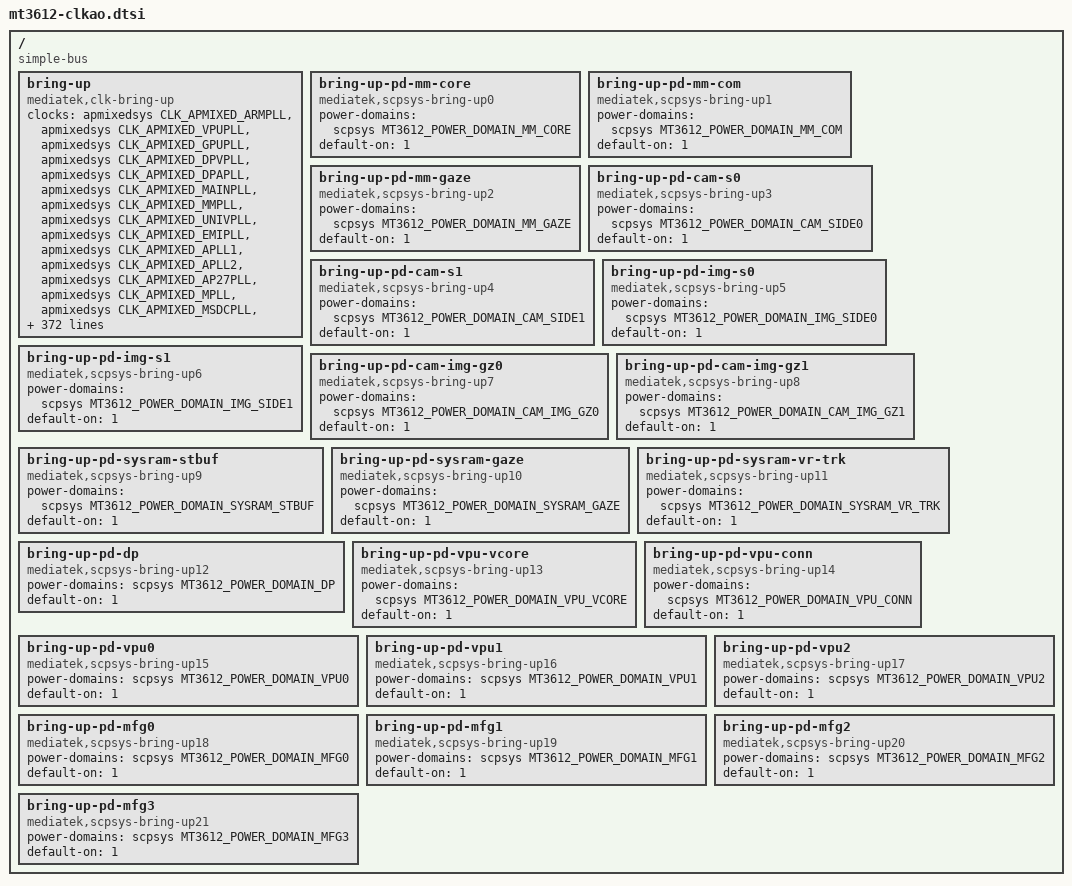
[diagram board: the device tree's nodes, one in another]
/ {
	compatible = "simple-bus";
	bring-up {
		compatible = "mediatek,clk-bring-up";
		clocks =
			<&apmixedsys CLK_APMIXED_ARMPLL>,
			<&apmixedsys CLK_APMIXED_VPUPLL>,
			<&apmixedsys CLK_APMIXED_GPUPLL>,
			<&apmixedsys CLK_APMIXED_DPVPLL>,
			<&apmixedsys CLK_APMIXED_DPAPLL>,
			<&apmixedsys CLK_APMIXED_MAINPLL>,
			<&apmixedsys CLK_APMIXED_MMPLL>,
			<&apmixedsys CLK_APMIXED_UNIVPLL>,
			<&apmixedsys CLK_APMIXED_EMIPLL>,
			<&apmixedsys CLK_APMIXED_APLL1>,
			<&apmixedsys CLK_APMIXED_APLL2>,
			<&apmixedsys CLK_APMIXED_AP27PLL>,
			<&apmixedsys CLK_APMIXED_MPLL>,
			<&apmixedsys CLK_APMIXED_MSDCPLL>,
			<&topckgen TOPCKGEN_SMI_CG>,
			<&topckgen TOPCKGEN_DSP_CG>,
			<&topckgen TOPCKGEN_IPU_IF_CG>,
			<&topckgen TOPCKGEN_SFLASH_CG>,
			<&topckgen TOPCKGEN_PWM_CG>,
			<&topckgen TOPCKGEN_CAMTG_CG>,
			<&topckgen TOPCKGEN_SENINF_CG>,
			<&topckgen TOPCKGEN_SENM0_CG>,
			<&topckgen TOPCKGEN_SENM1_CG>,
			<&topckgen TOPCKGEN_SENM2_CG>,
			<&topckgen TOPCKGEN_SENM3_CG>,
			<&topckgen TOPCKGEN_SENM4_CG>,
			<&topckgen TOPCKGEN_SENM5_CG>,
			<&topckgen TOPCKGEN_SENM6_CG>,
			<&topckgen TOPCKGEN_SENM7_CG>,
			<&topckgen TOPCKGEN_SENM8_CG>,
			<&topckgen TOPCKGEN_I2C_CG>,
			<&topckgen TOPCKGEN_UART_CG>,
			<&topckgen TOPCKGEN_SPI_CG>,
			<&topckgen TOPCKGEN_AXI_PERI_CG>,
			<&topckgen TOPCKGEN_USBH_SYS_CG>,
			<&topckgen TOPCKGEN_USBH_XCH_CG>,
			<&topckgen TOPCKGEN_USBD_SYS_CG>,
			<&topckgen TOPCKGEN_MSDC_CG>,
			<&topckgen TOPCKGEN_MSDC_HCLK_CG>,
			<&topckgen TOPCKGEN_AES_FDE_CG>,
			<&topckgen TOPCKGEN_AUD_INTBUS_CG>,
			<&topckgen TOPCKGEN_A1SYS_HP_CG>,
			<&topckgen TOPCKGEN_A2SYS_HP_CG>,
			<&topckgen TOPCKGEN_A3SYS_HP_CG>,
			<&topckgen TOPCKGEN_TDMIN_CG>,
			<&topckgen TOPCKGEN_TDMOUT_CG>,
			<&topckgen TOPCKGEN_PMICSPI_CG>,
			<&topckgen TOPCKGEN_MUTEXGEN_CG>,
			<&topckgen TOPCKGEN_STC_H27_CG>,
			<&topckgen TOPCKGEN_MFG_CG>,
			<&topckgen TOPCKGEN_CRYPTO_CG>,
			<&topckgen TOPCKGEN_IMG_S0_CG>,
			<&topckgen TOPCKGEN_IMG_S1_CG>,
			<&topckgen TOPCKGEN_MMSYS_COM_CG>,
			<&topckgen TOPCKGEN_FM_CG>,
			<&topckgen TOPCKGEN_MMSYS_CORE_CG>,
			<&topckgen TOPCKGEN_MM_SYSRAM0_CG>,
			<&topckgen TOPCKGEN_MM_SYSRAM1_CG>,
			<&topckgen TOPCKGEN_MM_SYSRAM2_CG>,
			<&topckgen TOPCKGEN_SENINF_GAZE_CG>,
			<&topckgen TOPCKGEN_CAM_S0_CG>,
			<&topckgen TOPCKGEN_CAM_S1_CG>,
			<&topckgen TOPCKGEN_CAM_GZ0_CG>,
			<&topckgen TOPCKGEN_CAM_GZ1_CG>,
			<&topckgen TOPCKGEN_MM_SYNCGEN_CG>,
			<&topckgen TOPCKGEN_ATB_CG>,
			<&topckgen TOPCKGEN_DISPPWM_CG>,
			<&topckgen TOPCKGEN_PMICGSPI_CG>,
			<&topckgen TOPCKGEN_DDDS_CG>,
			<&topckgen TOPCKGEN_DSP1_CG>,
			<&topckgen TOPCKGEN_DSP2_CG>,
			<&topckgen TOPCKGEN_DSP3_CG>,
			<&topckgen TOPCKGEN_HEADER_SYS_CG>,
			<&topckgen TOPCKGEN_DSI_REF_CG>,
			<&topckgen TOPCKGEN_SLICER_VID_CG>,
			<&topckgen TOPCKGEN_SLICER_DSC_CG>,
			<&topckgen TOPCKGEN_TPIU_CG>,
			<&topckgen TOPCKGEN_DDDS_VSP_CG>,
			<&topckgen TOPCKGEN_SCP_P_CK0_CG>,
			<&topckgen TOPCKGEN_SCP_P_CK1_CG>,
			<&topckgen TOPCKGEN_SCP_P_CK2_CG>,
			<&topckgen TOPCKGEN_SSUB_TOP_CK_EN>,
			<&topckgen TOPCKGEN_SSUB_PHY_CK_EN>,
			<&topckgen TOPCKGEN_SSUB_TOP_CK_EN_IP2>,
			<&topckgen TOPCKGEN_SSUB_PHY_CK_EN_IP2>,
			<&topckgen TOPCKGEN_F26M_DP_REF_CK_EN>,
			<&topckgen CLK_TOP_APLL12_DIV0>,
			<&topckgen CLK_TOP_APLL12_DIV1>,
			<&topckgen CLK_TOP_APLL12_DIV2>,
			<&topckgen CLK_TOP_APLL12_DIV3>,
			<&infracfg INFRACFG_AO_PMIC_CG_TMR>,
			<&infracfg INFRACFG_AO_PMIC_CG_AP>,
			<&infracfg INFRACFG_AO_PMIC_CG_MD>,
			<&infracfg INFRACFG_AO_PMIC_CG_CONN>,
			<&infracfg INFRACFG_AO_SCP_CG>,
			<&infracfg INFRACFG_AO_SEJ_CG>,
			<&infracfg INFRACFG_AO_APXGPT_CG>,
			<&infracfg INFRACFG_AO_DVFSRC_CG>,
			<&infracfg INFRACFG_AO_IO_TIMER_CG>,
			<&infracfg INFRACFG_AO_DEVAPC_MPU_CG>,
			<&infracfg INFRACFG_AO_FHCTL_CG>,
			<&infracfg INFRACFG_AO_PMIC_GSPI_CG>,
			<&infracfg INFRACFG_AO_AUXADC_CG>,
			<&infracfg INFRACFG_AO_DEVICE_APC_CG>,
			<&infracfg INFRACFG_AO_SMI_L2C_CG>,
			<&infracfg INFRACFG_AO_AUDIO_CG>,
			<&infracfg INFRACFG_AO_DRAMC_F26M_CG>,
			<&pericfg PERISYS_I2C9_CK_PDN>,
			<&pericfg PERISYS_I2C8_CK_PDN>,
			<&pericfg PERISYS_I2C7_CK_PDN>,
			<&pericfg PERISYS_I2C6_CK_PDN>,
			<&pericfg PERISYS_I2C5_CK_PDN>,
			<&pericfg PERISYS_I2C4_CK_PDN>,
			<&pericfg PERISYS_I2C3_CK_PDN>,
			<&pericfg PERISYS_I2C2_CK_PDN>,
			<&pericfg PERISYS_I2C1_CK_PDN>,
			<&pericfg PERISYS_I2C0_CK_PDN>,
			<&pericfg PERISYS_PWM15_CK_PDN>,
			<&pericfg PERISYS_PWM14_CK_PDN>,
			<&pericfg PERISYS_PWM13_CK_PDN>,
			<&pericfg PERISYS_PWM12_CK_PDN>,
			<&pericfg PERISYS_PWM11_CK_PDN>,
			<&pericfg PERISYS_PWM10_CK_PDN>,
			<&pericfg PERISYS_PWM9_CK_PDN>,
			<&pericfg PERISYS_PWM8_CK_PDN>,
			<&pericfg PERISYS_PWM7_CK_PDN>,
			<&pericfg PERISYS_PWM6_CK_PDN>,
			<&pericfg PERISYS_PWM5_CK_PDN>,
			<&pericfg PERISYS_PWM4_CK_PDN>,
			<&pericfg PERISYS_PWM3_CK_PDN>,
			<&pericfg PERISYS_PWM2_CK_PDN>,
			<&pericfg PERISYS_PWM1_CK_PDN>,
			<&pericfg PERISYS_PWM_CK_PDN>,
			<&pericfg PERISYS_SPI9_CK_PDN>,
			<&pericfg PERISYS_SPI8_CK_PDN>,
			<&pericfg PERISYS_SPI7_CK_PDN>,
			<&pericfg PERISYS_SPI6_CK_PDN>,
			<&pericfg PERISYS_SPI5_CK_PDN>,
			<&pericfg PERISYS_SPI4_CK_PDN>,
			<&pericfg PERISYS_SPI3_CK_PDN>,
			<&pericfg PERISYS_SPI2_CK_PDN>,
			<&pericfg PERISYS_SPI1_CK_PDN>,
			<&pericfg PERISYS_SPI0_CK_PDN>,
			<&pericfg PERISYS_UART9_CK_PDN>,
			<&pericfg PERISYS_UART8_CK_PDN>,
			<&pericfg PERISYS_UART7_CK_PDN>,
			<&pericfg PERISYS_UART6_CK_PDN>,
			<&pericfg PERISYS_UART5_CK_PDN>,
			<&pericfg PERISYS_UART4_CK_PDN>,
			<&pericfg PERISYS_UART3_CK_PDN>,
			<&pericfg PERISYS_UART2_CK_PDN>,
			<&pericfg PERISYS_UART1_CK_PDN>,
			<&pericfg PERISYS_UART0_CK_PDN>,
			<&pericfg PERISYS_MSDC0_AP_CK_PDN>,
			<&pericfg PERISYS_FLASH_CK_PDN>,
			<&pericfg PERISYS_USB_CK_PDN>,
			<&pericfg PERISYS_DISP_PWM1_CK_PDN>,
			<&pericfg PERISYS_DISP_PWM0_CK_PDN>,
			<&pericfg PERISYS_DEV_APC_CK_PDN>,
			<&pericfg PERISYS_DEBUGTOP_CK_PDN>,
			<&pericfg PERISYS_I2C19_CK_PDN>,
			<&pericfg PERISYS_I2C18_CK_PDN>,
			<&pericfg PERISYS_I2C17_CK_PDN>,
			<&pericfg PERISYS_I2C16_CK_PDN>,
			<&pericfg PERISYS_I2C15_CK_PDN>,
			<&pericfg PERISYS_I2C14_CK_PDN>,
			<&pericfg PERISYS_I2C13_CK_PDN>,
			<&pericfg PERISYS_I2C12_CK_PDN>,
			<&pericfg PERISYS_I2C11_CK_PDN>,
			<&pericfg PERISYS_I2C10_CK_PDN>,
			<&pericfg PERISYS_PWM32_CK_PDN>,
			<&pericfg PERISYS_PWM31_CK_PDN>,
			<&pericfg PERISYS_PWM30_CK_PDN>,
			<&pericfg PERISYS_PWM29_CK_PDN>,
			<&pericfg PERISYS_PWM28_CK_PDN>,
			<&pericfg PERISYS_PWM27_CK_PDN>,
			<&pericfg PERISYS_PWM26_CK_PDN>,
			<&pericfg PERISYS_PWM25_CK_PDN>,
			<&pericfg PERISYS_PWM24_CK_PDN>,
			<&pericfg PERISYS_PWM23_CK_PDN>,
			<&pericfg PERISYS_PWM22_CK_PDN>,
			<&pericfg PERISYS_PWM21_CK_PDN>,
			<&pericfg PERISYS_PWM20_CK_PDN>,
			<&pericfg PERISYS_PWM19_CK_PDN>,
			<&pericfg PERISYS_PWM18_CK_PDN>,
			<&pericfg PERISYS_PWM17_CK_PDN>,
			<&pericfg PERISYS_PWM16_CK_PDN>,
			<&mmsys_core MMSYS_CORE_SLCR0>,
			<&mmsys_core MMSYS_CORE_SLCR1>,
			<&mmsys_core MMSYS_CORE_SLCR2>,
			<&mmsys_core MMSYS_CORE_SLCR3>,
			<&mmsys_core MMSYS_CORE_MDP_RDMA0>,
			<&mmsys_core MMSYS_CORE_MDP_RDMA1>,
			<&mmsys_core MMSYS_CORE_MDP_RDMA2>,
			<&mmsys_core MMSYS_CORE_MDP_RDMA3>,
			<&mmsys_core MMSYS_CORE_MDP_PVRIC0>,
			<&mmsys_core MMSYS_CORE_MDP_PVRIC1>,
			<&mmsys_core MMSYS_CORE_MDP_PVRIC2>,
			<&mmsys_core MMSYS_CORE_MDP_PVRIC3>,
			<&mmsys_core MMSYS_CORE_DISP_RDMA0>,
			<&mmsys_core MMSYS_CORE_DISP_RDMA1>,
			<&mmsys_core MMSYS_CORE_DISP_RDMA2>,
			<&mmsys_core MMSYS_CORE_DISP_RDMA3>,
			<&mmsys_core MMSYS_CORE_DP_PAT_GEN0>,
			<&mmsys_core MMSYS_CORE_DP_PAT_GEN1>,
			<&mmsys_core MMSYS_CORE_DP_PAT_GEN2>,
			<&mmsys_core MMSYS_CORE_DP_PAT_GEN3>,
			<&mmsys_core MMSYS_CORE_LHC0>,
			<&mmsys_core MMSYS_CORE_LHC1>,
			<&mmsys_core MMSYS_CORE_LHC2>,
			<&mmsys_core MMSYS_CORE_LHC3>,
			<&mmsys_core MMSYS_CORE_DISP_WDMA0>,
			<&mmsys_core MMSYS_CORE_DISP_WDMA1>,
			<&mmsys_core MMSYS_CORE_DISP_WDMA2>,
			<&mmsys_core MMSYS_CORE_DISP_WDMA3>,
			<&mmsys_core MMSYS_CORE_DSC_MOUNT0>,
			<&mmsys_core MMSYS_CORE_DSC_MOUNT1>,
			<&mmsys_core MMSYS_CORE_DSC_MOUNT2>,
			<&mmsys_core MMSYS_CORE_DSC_MOUNT3>,
			<&mmsys_core MMSYS_CORE_DSI0_MM>,
			<&mmsys_core MMSYS_CORE_DSI1_MM>,
			<&mmsys_core MMSYS_CORE_DSI2_MM>,
			<&mmsys_core MMSYS_CORE_DSI3_MM>,
			<&mmsys_core MMSYS_CORE_DSI0_DIG>,
			<&mmsys_core MMSYS_CORE_DSI1_DIG>,
			<&mmsys_core MMSYS_CORE_DSI2_DIG>,
			<&mmsys_core MMSYS_CORE_DSI3_DIG>,
			<&mmsys_core MMSYS_CORE_CROP0>,
			<&mmsys_core MMSYS_CORE_CROP1>,
			<&mmsys_core MMSYS_CORE_CROP2>,
			<&mmsys_core MMSYS_CORE_CROP3>,
			<&mmsys_core MMSYS_CORE_RDMA_MOUT0>,
			<&mmsys_core MMSYS_CORE_RDMA_MOUT1>,
			<&mmsys_core MMSYS_CORE_RDMA_MOUT2>,
			<&mmsys_core MMSYS_CORE_RDMA_MOUT3>,
			<&mmsys_core MMSYS_CORE_RSZ0>,
			<&mmsys_core MMSYS_CORE_RSZ1>,
			<&mmsys_core MMSYS_CORE_RSZ_MOUT0>,
			<&mmsys_core MMSYS_CORE_P2S0>,
			<&mmsys_core MMSYS_CORE_DSC0>,
			<&mmsys_core MMSYS_CORE_DSC1>,
			<&mmsys_core MMSYS_CORE_DSI_LANE_SWAP>,
			<&mmsys_core MMSYS_CORE_SLICER_MM>,
			<&mmsys_core MMSYS_CORE_SLICER_VID>,
			<&mmsys_core MMSYS_CORE_SLICER_DSC>,
			<&mmsys_core MMSYS_CORE_LHC_SWAP>,
			<&mmsys_core MMSYS_CORE_SMI_LARB0>,
			<&mmsys_core MMSYS_CORE_SMI_LARB1>,
			<&mmsys_core MMSYS_CORE_SMI_LARB15>,
			<&mmsys_core MMSYS_CORE_SMI_LARB16>,
			<&mmsys_core MMSYS_CORE_LARB0_GALS>,
			<&mmsys_core MMSYS_CORE_LARB1_GALS>,
			<&mmsys_core MMSYS_CORE_LARB15_GALS>,
			<&mmsys_core MMSYS_CORE_LARB16_GALS>,
			<&mmsys_core MMSYS_CORE_RBFC0>,
			<&mmsys_core MMSYS_CORE_RBFC1>,
			<&mmsys_core MMSYS_CORE_RBFC2>,
			<&mmsys_core MMSYS_CORE_RBFC3>,
			<&mmsys_core MMSYS_CORE_SBRC>,
			<&mmsys_core MMSYS_CORE_MM_FAKE_ENG>,
			<&mmsys_core MMSYS_CORE_EVENT_TX>,
			<&mmsys_core MMSYS_CORE_CAMERA_SYNC>,
			<&mmsys_core MMSYS_CORE_MUTEX>,
			<&mmsys_core MMSYS_CORE_MUTEX_26M>,
			<&mmsys_core MMSYS_CORE_CRC>,
			<&mmsys_com MMSYS_CMM_PADDING0>,
			<&mmsys_com MMSYS_CMM_PADDING1>,
			<&mmsys_com MMSYS_CMM_PADDING2>,
			<&mmsys_com MMSYS_CMM_MDP_WPE_1_tx>,
			<&mmsys_com MMSYS_CMM_MDP_WPE_1_1_tx>,
			<&mmsys_com MMSYS_CMM_MDP_WPE_1_2_tx>,
			<&mmsys_com MMSYS_CMM_MDP_WPE_1>,
			<&mmsys_com MMSYS_CMM_MDP_FE>,
			<&mmsys_com MMSYS_CMM_WDMA_0>,
			<&mmsys_com MMSYS_CMM_WDMA_1>,
			<&mmsys_com MMSYS_CMM_WDMA_2>,
			<&mmsys_com MMSYS_CMM_MDP_FM>,
			<&mmsys_com MMSYS_CMM_RSZ_0>,
			<&mmsys_com MMSYS_CMM_RSZ_1>,
			<&mmsys_com MMSYS_CMM_MUTEX>,
			<&mmsys_com MMSYS_CMM_SMI_COMMON>,
			<&mmsys_com MMSYS_CMM_SMI_LARB3>,
			<&mmsys_com MMSYS_CMM_SMI_LARB21>,
			<&mmsys_com MMSYS_CMM_SMI_LARB2>,
			<&mmsys_com MMSYS_CMM_SMI_LARB20>,
			<&mmsys_com MMSYS_CMM_RBFC_REN_WPE1>,
			<&mmsys_com MMSYS_CMM_LARB2_FAKE_ENG>,
			<&mmsys_com MMSYS_CMM_SIDE_3_IN_CK_TX>,
			<&mmsys_com MMSYS_CMM_SIDE_2_IN_CK_TX>,
			<&mmsys_com MMSYS_CMM_SIDE_1_IN_CK_TX>,
			<&mmsys_com MMSYS_CMM_SIDE_0_IN_CK_TX>,
			<&mmsys_gaze MMSYS_GAZE_WPE_0_tx>,
			<&mmsys_gaze MMSYS_GAZE_WPE_0>,
			<&mmsys_gaze MMSYS_GAZE_WDMA_GAZE>,
			<&mmsys_gaze MMSYS_GAZE_MUTEX>,
			<&mmsys_gaze MMSYS_GAZE_SMI_LARB4>,
			<&mmsys_gaze MMSYS_GAZE_SMI_LARB22>,
			<&mmsys_gaze MMSYS_GAZE_RBFC_REN_WPE0>,
			<&mmsys_gaze MMSYS_GAZE_LARB4_FAKE_ENG>,
			<&mmsys_gaze MMSYS_GAZE_GAZE0_IN_CK_TX>,
			<&mmsys_gaze MMSYS_GAZE_GAZE1_IN_CK_TX>,
			<&vpusys_vcore VPUSYS_VCORE_AHB_CG>,
			<&vpusys_vcore VPUSYS_VCORE_AXI_CG>,
			<&vpusys_vconn VPUSYS_CONN_AHB_CG>,
			<&vpusys_vconn VPUSYS_CONN_AXI_CG>,
			<&vpusys_vconn VPUSYS_CONN_VPU_CG>,
			<&vpusys_core0 VPUSYS_CORE_0_VPU_CG>,
			<&vpusys_core0 VPUSYS_CORE_0_AXI_M_CG>,
			<&vpusys_core0 VPUSYS_CORE_0_JTAG>,
			<&vpusys_core1 VPUSYS_CORE_1_VPU_CG>,
			<&vpusys_core1 VPUSYS_CORE_1_AXI_M_CG>,
			<&vpusys_core1 VPUSYS_CORE_1_JTAG>,
			<&vpusys_core2 VPUSYS_CORE_2_VPU_CG>,
			<&vpusys_core2 VPUSYS_CORE_2_AXI_M_CG>,
			<&vpusys_core2 VPUSYS_CORE_2_JTAG>,
			<&audio_top AUDIO_TOP_PDN_TDMIN_BCK>,
			<&audio_top AUDIO_TOP_PDN_A3SYS>,
			<&audio_top AUDIO_TOP_PDN_A2SYS>,
			<&audio_top AUDIO_TOP_PDN_A1SYS>,
			<&audio_top AUDIO_TOP_PDN_DPRX_BCK>,
			<&audio_top AUDIO_TOP_PDN_TDMOUT_BCK>,
			<&audio_top AUDIO_TOP_PDN_AFE>,
			<&audio_top AUDIO_TOP_I2S_IN_CLK_CG>,
			<&audio_top AUDIO_TOP_I2S_OUT_CLK_CG>,
			<&camsys_gz0 CAMSYS_GZ0_RBFC_RRZO_0_CGPDN>,
			<&camsys_gz0 CAMSYS_GZ0_CAMSV_CGPDN>,
			<&camsys_gz0 CAMSYS_GZ0_SENINF_CGPDN>,
			<&camsys_gz0 CAMSYS_GZ0_CAMTG_CGPDN>,
			<&camsys_gz0 CAMSYS_GZ0_CAM_0_CGPDN>,
			<&camsys_gz0 CAMSYS_GZ0_SYSRAM_LARBX_CGPDN>,
			<&camsys_gz0 CAMSYS_GZ0_LARBX_CGPDN>,
			<&camsys_gz1 CAMSYS_GZ1_RBFC_RRZO_0_CGPDN>,
			<&camsys_gz1 CAMSYS_GZ1_CAMSV_CGPDN>,
			<&camsys_gz1 CAMSYS_GZ1_SENINF_CGPDN>,
			<&camsys_gz1 CAMSYS_GZ1_CAMTG_CGPDN>,
			<&camsys_gz1 CAMSYS_GZ1_CAM_0_CGPDN>,
			<&camsys_gz1 CAMSYS_GZ1_SYSRAM_LARBX_CGPDN>,
			<&camsys_gz1 CAMSYS_GZ1_LARBX_CGPDN>,
			<&imgsys_gz0 IMGSYS_GZ0_RBFC_IMG3O_A_CGPDN>,
			<&imgsys_gz0 IMGSYS_GZ0_RBFC_IMGI_A_CGPDN>,
			<&imgsys_gz0 IMGSYS_GZ0_DIP_A_CGPDN>,
			<&imgsys_gz1 IMGSYS_GZ1_RBFC_IMG3O_A_CGPDN>,
			<&imgsys_gz1 IMGSYS_GZ1_RBFC_IMGI_A_CGPDN>,
			<&imgsys_gz1 IMGSYS_GZ1_DIP_A_CGPDN>,
			<&camsys_side0 CAMSYS_SIDE0_BE1_CGPDN>,
			<&camsys_side0 CAMSYS_SIDE0_BE0_CGPDN>,
			<&camsys_side0 CAMSYS_SIDE0_RBFC_RRZO_1_CGPDN>,
			<&camsys_side0 CAMSYS_SIDE0_RBFC_RRZO_0_CGPDN>,
			<&camsys_side0 CAMSYS_SIDE0_CCU_CGPDN>,
			<&camsys_side0 CAMSYS_SIDE0_CAMSV_CGPDN>,
			<&camsys_side0 CAMSYS_SIDE0_SENINF_CGPDN>,
			<&camsys_side0 CAMSYS_SIDE0_CAMTG_CGPDN>,
			<&camsys_side0 CAMSYS_SIDE0_CAM_1_CGPDN>,
			<&camsys_side0 CAMSYS_SIDE0_CAM_0_CGPDN>,
			<&camsys_side0 CAMSYS_SIDE0_SYSRAM_LARBX_CGPDN>,
			<&camsys_side0 CAMSYS_SIDE0_LARBX_CGPDN>,
			<&camsys_side1 CAMSYS_SIDE1_BE1_CGPDN>,
			<&camsys_side1 CAMSYS_SIDE1_BE0_CGPDN>,
			<&camsys_side1 CAMSYS_SIDE1_RBFC_RRZO_1_CGPDN>,
			<&camsys_side1 CAMSYS_SIDE1_RBFC_RRZO_0_CGPDN>,
			<&camsys_side1 CAMSYS_SIDE1_CCU_CGPDN>,
			<&camsys_side1 CAMSYS_SIDE1_CAMSV_CGPDN>,
			<&camsys_side1 CAMSYS_SIDE1_SENINF_CGPDN>,
			<&camsys_side1 CAMSYS_SIDE1_CAMTG_CGPDN>,
			<&camsys_side1 CAMSYS_SIDE1_CAM_1_CGPDN>,
			<&camsys_side1 CAMSYS_SIDE1_CAM_0_CGPDN>,
			<&camsys_side1 CAMSYS_SIDE1_SYSRAM_LARBX_CGPDN>,
			<&camsys_side1 CAMSYS_SIDE1_LARBX_CGPDN>,
			<&imgsys_side0 IMGSYS_SIDE0_RBFC_IMG3O_B_CGPDN>,
			<&imgsys_side0 IMGSYS_SIDE0_RBFC_IMG3O_A_CGPDN>,
			<&imgsys_side0 IMGSYS_SIDE0_RBFC_IMGI_B_CGPDN>,
			<&imgsys_side0 IMGSYS_SIDE0_RBFC_IMGI_A_CGPDN>,
			<&imgsys_side0 IMGSYS_SIDE0_SYSRAM_LARBX_1_CGPDN>,
			<&imgsys_side0 IMGSYS_SIDE0_DIP_B_CGPDN>,
			<&imgsys_side0 IMGSYS_SIDE0_DIP_A_CGPDN>,
			<&imgsys_side0 IMGSYS_SIDE0_SYSRAM_LARBX_CGPDN>,
			<&imgsys_side0 IMGSYS_SIDE0_LARBX_CGPDN>,
			<&imgsys_side1 IMGSYS_SIDE1_RBFC_IMG3O_B_CGPDN>,
			<&imgsys_side1 IMGSYS_SIDE1_RBFC_IMG3O_A_CGPDN>,
			<&imgsys_side1 IMGSYS_SIDE1_RBFC_IMGI_B_CGPDN>,
			<&imgsys_side1 IMGSYS_SIDE1_RBFC_IMGI_A_CGPDN>,
			<&imgsys_side1 IMGSYS_SIDE1_SYSRAM_LARBX_1_CGPDN>,
			<&imgsys_side1 IMGSYS_SIDE1_DIP_B_CGPDN>,
			<&imgsys_side1 IMGSYS_SIDE1_DIP_A_CGPDN>,
			<&imgsys_side1 IMGSYS_SIDE1_SYSRAM_LARBX_CGPDN>,
			<&imgsys_side1 IMGSYS_SIDE1_LARBX_CGPDN>;
		clock-names =
			"0", "1", "2", "3", "4", "5", "6", "7", "8", "9",
			"10", "11", "12", "13", "14", "15", "16", "17", "18",
			"19", "20", "21", "22", "23", "24", "25", "26", "27",
			"28", "29", "30", "31", "32", "33", "34", "35", "36",
			"37", "38", "39", "40", "41", "42", "43", "44", "45",
			"46", "47", "48", "49", "50", "51", "52", "53", "54",
			"55", "56", "57", "58", "59", "60", "61", "62", "63",
			"64", "65", "66", "67", "68", "69", "70", "71", "72",
			"73", "74", "75", "76", "77", "78", "79", "80", "81",
			"82", "83", "84", "85", "86", "87", "88", "89", "90",
			"91", "92", "93", "94", "95", "96", "97", "98", "99",
			"100", "101", "102", "103", "104", "105", "106", "107",
			"108", "109", "110", "111", "112", "113", "114", "115",
			"116", "117", "118", "119", "120", "121", "122", "123",
			"124", "125", "126", "127", "128", "129", "130", "131",
			"132", "133", "134", "135", "136", "137", "138", "139",
			"140", "141", "142", "143", "144", "145", "146", "147",
			"148", "149", "150", "151", "152", "153", "154", "155",
			"156", "157", "158", "159", "160", "161", "162", "163",
			"164", "165", "166", "167", "168", "169", "170", "171",
			"172", "173", "174", "175", "176", "177", "178", "179",
			"180", "181", "182", "183", "184", "185", "186", "187",
			"188", "189", "190", "191", "192", "193", "194", "195",
			"196", "197", "198", "199", "200", "201", "202", "203",
			"204", "205", "206", "207", "208", "209", "210", "211",
			"212", "213", "214", "215", "216", "217", "218", "219",
			"220", "221", "222", "223", "224", "225", "226", "227",
			"228", "229", "230", "231", "232", "233", "234", "235",
			"236", "237", "238", "239", "240", "241", "242", "243",
			"244", "245", "246", "247", "248", "249", "250", "251",
			"252", "253", "254", "255", "256", "257", "258", "259",
			"260", "261", "262", "263", "264", "265", "266", "267",
			"268", "269", "270", "271", "272", "273", "274", "275",
			"276", "277", "278", "279", "280", "281", "282", "283",
			"284", "285", "286", "287", "288", "289", "290", "291",
			"292", "293", "294", "295", "296", "297", "298", "299",
			"300", "301", "302", "303", "304", "305", "306", "307",
			"308", "309", "310", "311", "312", "313", "314", "315",
			"316", "317", "318", "319", "320", "321", "322", "323",
			"324", "325", "326", "327", "328", "329", "330", "331",
			"332", "333", "334", "335", "336", "337", "338", "339",
			"340", "341", "342", "343", "344", "345", "346", "347",
			"348", "349", "350", "351", "352", "353", "354", "355",
			"356", "357", "358", "359", "360", "361", "362", "363",
			"364", "365", "366", "367", "368", "369", "370", "371",
			"372", "373", "374", "375", "376", "377", "378", "379",
			"380", "381", "382", "383", "384", "385", "386";
	};
	bring-up-pd-mm-core {
		compatible = "mediatek,scpsys-bring-up0";
		power-domains = <&scpsys MT3612_POWER_DOMAIN_MM_CORE>;
		default-on = <1>;
	};
	bring-up-pd-mm-com {
		compatible = "mediatek,scpsys-bring-up1";
		power-domains = <&scpsys MT3612_POWER_DOMAIN_MM_COM>;
		default-on = <1>;
	};
	bring-up-pd-mm-gaze {
		compatible = "mediatek,scpsys-bring-up2";
		power-domains = <&scpsys MT3612_POWER_DOMAIN_MM_GAZE>;
		default-on = <1>;
	};
	bring-up-pd-cam-s0 {
		compatible = "mediatek,scpsys-bring-up3";
		power-domains = <&scpsys MT3612_POWER_DOMAIN_CAM_SIDE0>;
		default-on = <1>;
	};
	bring-up-pd-cam-s1 {
		compatible = "mediatek,scpsys-bring-up4";
		power-domains = <&scpsys MT3612_POWER_DOMAIN_CAM_SIDE1>;
		default-on = <1>;
	};
	bring-up-pd-img-s0 {
		compatible = "mediatek,scpsys-bring-up5";
		power-domains = <&scpsys MT3612_POWER_DOMAIN_IMG_SIDE0>;
		default-on = <1>;
	};
	bring-up-pd-img-s1 {
		compatible = "mediatek,scpsys-bring-up6";
		power-domains = <&scpsys MT3612_POWER_DOMAIN_IMG_SIDE1>;
		default-on = <1>;
	};
	bring-up-pd-cam-img-gz0 {
		compatible = "mediatek,scpsys-bring-up7";
		power-domains = <&scpsys MT3612_POWER_DOMAIN_CAM_IMG_GZ0>;
		default-on = <1>;
	};
	bring-up-pd-cam-img-gz1 {
		compatible = "mediatek,scpsys-bring-up8";
		power-domains = <&scpsys MT3612_POWER_DOMAIN_CAM_IMG_GZ1>;
		default-on = <1>;
	};
	bring-up-pd-sysram-stbuf {
		compatible = "mediatek,scpsys-bring-up9";
		power-domains = <&scpsys MT3612_POWER_DOMAIN_SYSRAM_STBUF>;
		default-on = <1>;
	};
	bring-up-pd-sysram-gaze {
		compatible = "mediatek,scpsys-bring-up10";
		power-domains = <&scpsys MT3612_POWER_DOMAIN_SYSRAM_GAZE>;
		default-on = <1>;
	};
	bring-up-pd-sysram-vr-trk {
		compatible = "mediatek,scpsys-bring-up11";
		power-domains = <&scpsys MT3612_POWER_DOMAIN_SYSRAM_VR_TRK>;
		default-on = <1>;
	};
	bring-up-pd-dp {
		compatible = "mediatek,scpsys-bring-up12";
		power-domains = <&scpsys MT3612_POWER_DOMAIN_DP>;
		default-on = <1>;
	};
	bring-up-pd-vpu-vcore {
		compatible = "mediatek,scpsys-bring-up13";
		power-domains = <&scpsys MT3612_POWER_DOMAIN_VPU_VCORE>;
		default-on = <1>;
	};
	bring-up-pd-vpu-conn {
		compatible = "mediatek,scpsys-bring-up14";
		power-domains = <&scpsys MT3612_POWER_DOMAIN_VPU_CONN>;
		default-on = <1>;
	};
	bring-up-pd-vpu0 {
		compatible = "mediatek,scpsys-bring-up15";
		power-domains = <&scpsys MT3612_POWER_DOMAIN_VPU0>;
		default-on = <1>;
	};
	bring-up-pd-vpu1 {
		compatible = "mediatek,scpsys-bring-up16";
		power-domains = <&scpsys MT3612_POWER_DOMAIN_VPU1>;
		default-on = <1>;
	};
	bring-up-pd-vpu2 {
		compatible = "mediatek,scpsys-bring-up17";
		power-domains = <&scpsys MT3612_POWER_DOMAIN_VPU2>;
		default-on = <1>;
	};
	bring-up-pd-mfg0 {
		compatible = "mediatek,scpsys-bring-up18";
		power-domains = <&scpsys MT3612_POWER_DOMAIN_MFG0>;
		default-on = <1>;
	};
	bring-up-pd-mfg1 {
		compatible = "mediatek,scpsys-bring-up19";
		power-domains = <&scpsys MT3612_POWER_DOMAIN_MFG1>;
		default-on = <1>;
	};
	bring-up-pd-mfg2 {
		compatible = "mediatek,scpsys-bring-up20";
		power-domains = <&scpsys MT3612_POWER_DOMAIN_MFG2>;
		default-on = <1>;
	};
	bring-up-pd-mfg3 {
		compatible = "mediatek,scpsys-bring-up21";
		power-domains = <&scpsys MT3612_POWER_DOMAIN_MFG3>;
		default-on = <1>;
	};
};
